VERSION "1.0"

NS_ :

BS_:

BU_: ECU1 ECU2

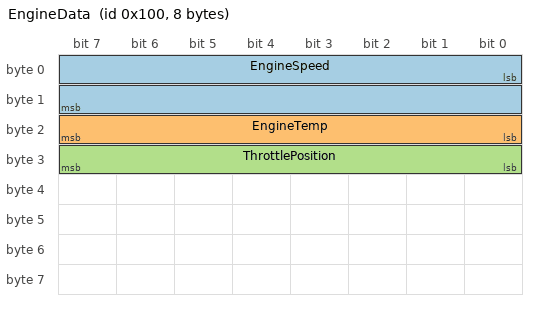
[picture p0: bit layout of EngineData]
BO_ 256 EngineData: 8 ECU1
 SG_ EngineSpeed : 0|16@1+ (0.25,0) [0|16383.75] "rpm" Vector__XXX
 SG_ EngineTemp : 16|8@1+ (1,-40) [-40|215] "degC" Vector__XXX
 SG_ ThrottlePosition : 24|8@1+ (0.392157,0) [0|100] "%" Vector__XXX

BO_ 512 VehicleStatus: 8 ECU2
 SG_ VehicleSpeed : 0|16@1+ (0.01,0) [0|655.35] "km/h" Vector__XXX
 SG_ Odometer : 16|24@1+ (0.1,0) [0|1677721.5] "km" Vector__XXX

CM_ BO_ 256 "Engine sensor data";
CM_ SG_ 256 EngineSpeed "Engine rotational speed";
CM_ SG_ 256 EngineTemp "Coolant temperature";
